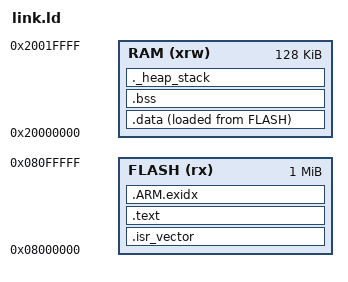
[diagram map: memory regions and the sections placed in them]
/* STM32F407VG: 1 MB flash, 128 KB ana SRAM (CCM RAM kullanılmaz) */
ENTRY(Reset_Handler)

MEMORY
{
    FLASH (rx)  : ORIGIN = 0x08000000, LENGTH = 1024K
    RAM   (xrw) : ORIGIN = 0x20000000, LENGTH = 128K
}

_estack = ORIGIN(RAM) + LENGTH(RAM);

SECTIONS
{
    .isr_vector : { KEEP(*(.isr_vector)) } > FLASH

    .text :
    {
        *(.text*)
        *(.rodata*)
        KEEP(*(.init))
        KEEP(*(.fini))
        . = ALIGN(4);
    } > FLASH

    .ARM.exidx : { *(.ARM.exidx*) } > FLASH

    _sidata = LOADADDR(.data);

    .data :
    {
        _sdata = .;
        *(.data*)
        . = ALIGN(4);
        _edata = .;
    } > RAM AT > FLASH

    .bss :
    {
        _sbss = .;
        *(.bss*)
        *(COMMON)
        . = ALIGN(4);
        _ebss = .;
    } > RAM

    ._heap_stack :
    {
        . = ALIGN(8);
        PROVIDE(end = .);
        PROVIDE(_end = .);
        . = . + 0x400;  /* yığın için ayrılan en az alan */
    } > RAM
}
